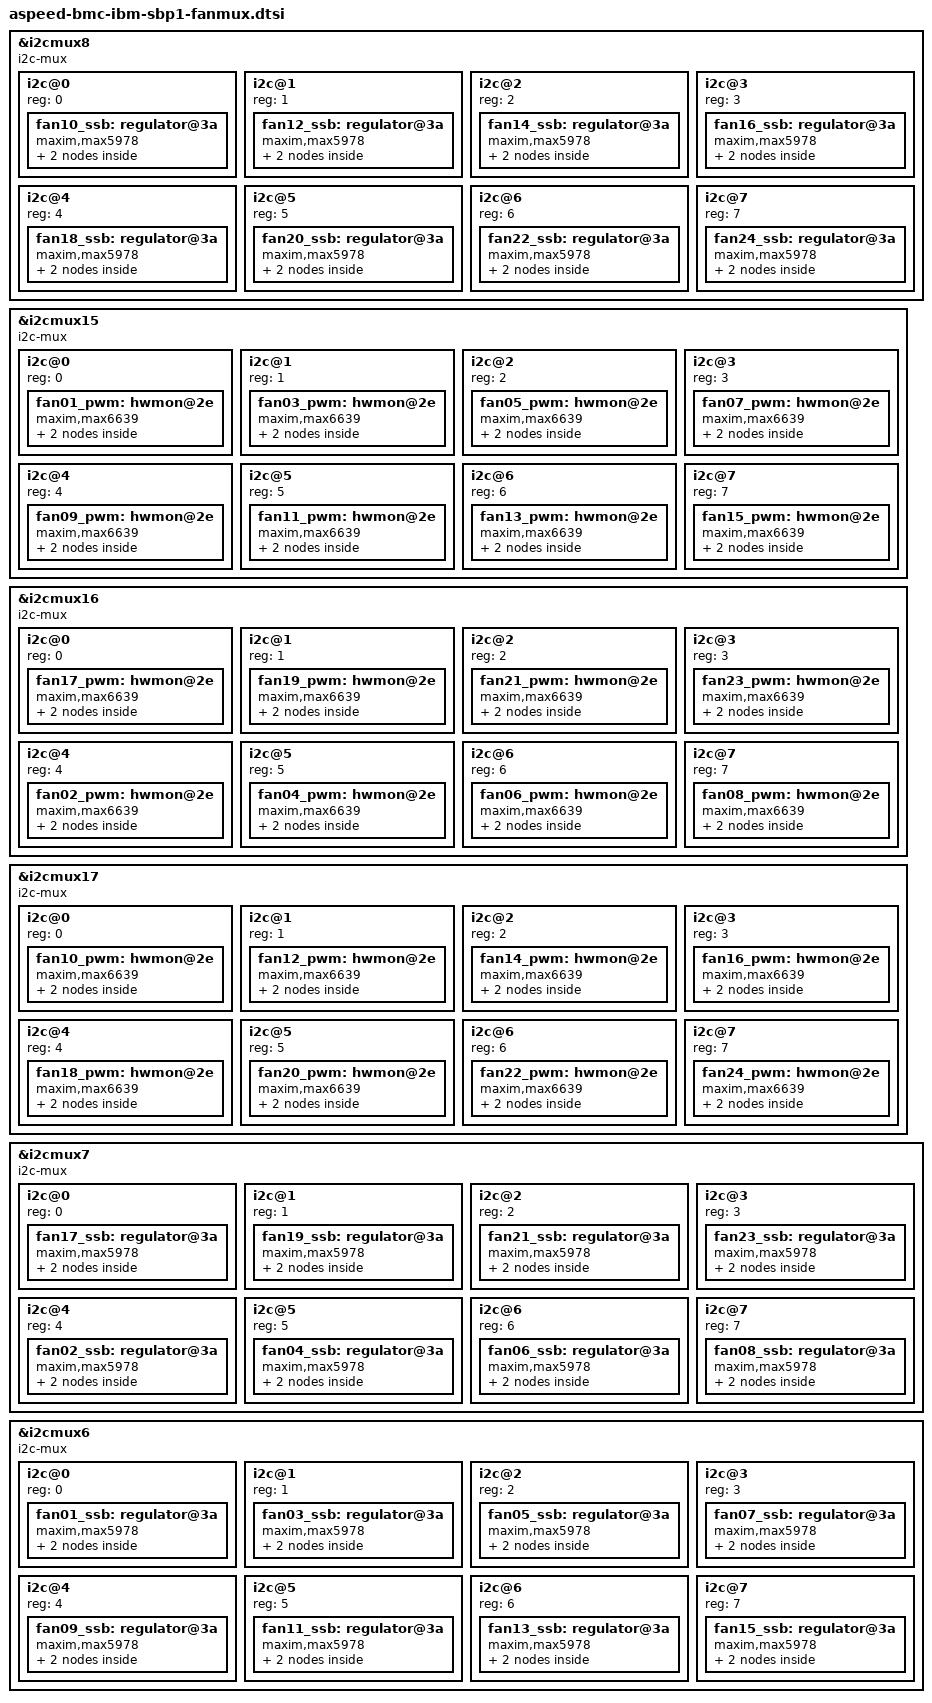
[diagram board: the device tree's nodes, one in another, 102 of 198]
&i2cmux8 {
	i2c@0 { // MUX_FAN10_SSB
		#address-cells = <1>;
		#size-cells = <0>;
		reg = <0>;
		fan10_ssb: regulator@3a {
			reg = <0x3a>;
			compatible = "maxim,max5978";
			#io-channel-cells = <1>;
			vin-supply = <&p3v3_aux>;
			vbus-supply = <&p3v3_aux>;
			vss1-supply = <&p12v_a>;
			interrupt-parent = <&smb_svc_pex_fan_alert>;
			interrupts = <9 IRQ_TYPE_LEVEL_LOW>; // FAN10_SSB_ALERT_N

			regulators {
				sw0_fan10_ssb: SW0 {
					vss1-supply = <&p12v_a>;
					regulator-compatible = "SW0";
					regulator-name = "fan10_supply";
					shunt-resistor-micro-ohms = <10000>;
					regulator-over-current-protection;
					regulator-oc-protection-microamp = <3400000>;
					regulator-enable-ramp-delay = <1000>;
				};
			};
		};

	};
	i2c@1 { // MUX_FAN12_SSB
		#address-cells = <1>;
		#size-cells = <0>;
		reg = <1>;
		fan12_ssb: regulator@3a {
			reg = <0x3a>;
			compatible = "maxim,max5978";
			#io-channel-cells = <1>;
			vin-supply = <&p3v3_aux>;
			vbus-supply = <&p3v3_aux>;
			vss1-supply = <&p12v_a>;
			interrupt-parent = <&smb_svc_pex_fan_alert>;
			interrupts = <11 IRQ_TYPE_LEVEL_LOW>; // FAN12_SSB_ALERT_N

			regulators {
				sw0_fan12_ssb: SW0 {
					vss1-supply = <&p12v_a>;
					regulator-compatible = "SW0";
					regulator-name = "fan12_supply";
					shunt-resistor-micro-ohms = <10000>;
					regulator-over-current-protection;
					regulator-oc-protection-microamp = <3400000>;
					regulator-enable-ramp-delay = <1000>;
				};
			};
		};

	};
	i2c@2 { // MUX_FAN14_SSB
		#address-cells = <1>;
		#size-cells = <0>;
		reg = <2>;
		fan14_ssb: regulator@3a {
			reg = <0x3a>;
			compatible = "maxim,max5978";
			#io-channel-cells = <1>;
			vin-supply = <&p3v3_aux>;
			vbus-supply = <&p3v3_aux>;
			vss1-supply = <&p12v_a>;
			interrupt-parent = <&smb_svc_pex_fan_alert>;
			interrupts = <13 IRQ_TYPE_LEVEL_LOW>; // FAN14_SSB_ALERT_N

			regulators {
				sw0_fan14_ssb: SW0 {
					vss1-supply = <&p12v_a>;
					regulator-compatible = "SW0";
					regulator-name = "fan14_supply";
					shunt-resistor-micro-ohms = <10000>;
					regulator-over-current-protection;
					regulator-oc-protection-microamp = <3400000>;
					regulator-enable-ramp-delay = <1000>;
				};
			};
		};
	};
	i2c@3 { // MUX_FAN16_SSB
		#address-cells = <1>;
		#size-cells = <0>;
		reg = <3>;
		fan16_ssb: regulator@3a {
			reg = <0x3a>;
			compatible = "maxim,max5978";
			#io-channel-cells = <1>;
			vin-supply = <&p3v3_aux>;
			vbus-supply = <&p3v3_aux>;
			vss1-supply = <&p12v_a>;
			interrupt-parent = <&smb_svc_pex_fan_alert>;
			interrupts = <15 IRQ_TYPE_LEVEL_LOW>; // FAN16_SSB_ALERT_N

			regulators {
				sw0_fan16_ssb: SW0 {
					vss1-supply = <&p12v_a>;
					regulator-compatible = "SW0";
					regulator-name = "fan16_supply";
					shunt-resistor-micro-ohms = <10000>;
					regulator-over-current-protection;
					regulator-oc-protection-microamp = <3400000>;
					regulator-enable-ramp-delay = <1000>;
				};
			};
		};
	};
	i2c@4 { // MUX_FAN18_SSB
		#address-cells = <1>;
		#size-cells = <0>;
		reg = <4>;
		fan18_ssb: regulator@3a {
			reg = <0x3a>;
			compatible = "maxim,max5978";
			#io-channel-cells = <1>;
			vin-supply = <&p3v3_aux>;
			vbus-supply = <&p3v3_aux>;
			vss1-supply = <&p12v_a>;
			interrupt-parent = <&smb_svc_pex_fan_alert>;
			interrupts = <17 IRQ_TYPE_LEVEL_LOW>; // FAN18_SSB_ALERT_N

			regulators {
				sw0_fan18_ssb: SW0 {
					vss1-supply = <&p12v_a>;
					regulator-compatible = "SW0";
					regulator-name = "fan18_supply";
					shunt-resistor-micro-ohms = <10000>;
					regulator-over-current-protection;
					regulator-oc-protection-microamp = <3400000>;
					regulator-enable-ramp-delay = <1000>;
				};
			};
		};
	};
	i2c@5 { // MUX_FAN20_SSB
		#address-cells = <1>;
		#size-cells = <0>;
		reg = <5>;
		fan20_ssb: regulator@3a {
			reg = <0x3a>;
			compatible = "maxim,max5978";
			#io-channel-cells = <1>;
			vin-supply = <&p3v3_aux>;
			vbus-supply = <&p3v3_aux>;
			vss1-supply = <&p12v_a>;
			interrupt-parent = <&smb_svc_pex_fan_alert>;
			interrupts = <19 IRQ_TYPE_LEVEL_LOW>; // FAN20_SSB_ALERT_N

			regulators {
				sw0_fan20_ssb: SW0 {
					vss1-supply = <&p12v_a>;
					regulator-compatible = "SW0";
					regulator-name = "fan20_supply";
					shunt-resistor-micro-ohms = <10000>;
					regulator-over-current-protection;
					regulator-oc-protection-microamp = <3400000>;
					regulator-enable-ramp-delay = <1000>;
				};
			};
		};
	};
	i2c@6 { // MUX_FAN22_SSB
		#address-cells = <1>;
		#size-cells = <0>;
		reg = <6>;
		fan22_ssb: regulator@3a {
			reg = <0x3a>;
			compatible = "maxim,max5978";
			#io-channel-cells = <1>;
			vin-supply = <&p3v3_aux>;
			vbus-supply = <&p3v3_aux>;
			vss1-supply = <&p12v_a>;
			interrupt-parent = <&smb_svc_pex_fan_alert>;
			interrupts = <21 IRQ_TYPE_LEVEL_LOW>; // FAN22_SSB_ALERT_N

			regulators {
				sw0_fan22_ssb: SW0 {
					vss1-supply = <&p12v_a>;
					regulator-compatible = "SW0";
					regulator-name = "fan22_supply";
					shunt-resistor-micro-ohms = <10000>;
					regulator-over-current-protection;
					regulator-oc-protection-microamp = <3400000>;
					regulator-enable-ramp-delay = <1000>;
				};
			};
		};
	};
	i2c@7 { // MUX_FAN24_SSB
		#address-cells = <1>;
		#size-cells = <0>;
		reg = <7>;
		fan24_ssb: regulator@3a {
			reg = <0x3a>;
			compatible = "maxim,max5978";
			#io-channel-cells = <1>;
			vin-supply = <&p3v3_aux>;
			vbus-supply = <&p3v3_aux>;
			vss1-supply = <&p12v_a>;
			interrupt-parent = <&smb_svc_pex_fan_alert>;
			interrupts = <23 IRQ_TYPE_LEVEL_LOW>; // FAN24_SSB_ALERT_N

			regulators {
				sw0_fan24_ssb: SW0 {
					vss1-supply = <&p12v_a>;
					regulator-compatible = "SW0";
					regulator-name = "fan24_supply";
					shunt-resistor-micro-ohms = <10000>;
					regulator-over-current-protection;
					regulator-oc-protection-microamp = <3400000>;
					regulator-enable-ramp-delay = <1000>;
				};
			};
		};
	};
};

&i2cmux15 {
	i2c@0 { // MUX_FAN01_PWM
		#address-cells = <1>;
		#size-cells = <0>;
		reg = <0>;
		fan01_pwm: hwmon@2e {
			compatible = "maxim,max6639";
			#address-cells = <1>;
			#size-cells = <0>;
			reg = <0x2e>;
			interrupt-parent = <&smb_svc_pex_fan_alert>;
			interrupts = <27 IRQ_TYPE_LEVEL_LOW>; // FAN01_PWM_ALERT_N
			fan-supply = <&sw0_fan01_ssb>;
			channel@0 {
				reg = <0>;
				pwm-polarity = <1>;
				pulses-per-revolution = <1>;
				rpm-range = <16000>;
				pwm-init = <90>;
				maxim,disable-therm-full-speed;
			};
			channel@1 {
				reg = <1>;
				pwm-polarity = <1>;
				pulses-per-revolution = <1>;
				rpm-range = <16000>;
				pwm-init = <90>;
				maxim,disable-therm-full-speed;
			};
		};
	};
	i2c@1 { // MUX_FAN03_PWM
		#address-cells = <1>;
		#size-cells = <0>;
		reg = <1>;
		fan03_pwm: hwmon@2e {
			compatible = "maxim,max6639";
			#address-cells = <1>;
			#size-cells = <0>;
			reg = <0x2e>;
			interrupt-parent = <&smb_svc_pex_fan_alert>;
			interrupts = <29 IRQ_TYPE_LEVEL_LOW>; // FAN03_PWM_ALERT_N
			fan-supply = <&sw0_fan03_ssb>;
			channel@0 {
				reg = <0>;
				pwm-polarity = <1>;
				pulses-per-revolution = <1>;
				rpm-range = <16000>;
				pwm-init = <90>;
				maxim,disable-therm-full-speed;
			};
			channel@1 {
				reg = <1>;
				pwm-polarity = <1>;
				pulses-per-revolution = <1>;
				rpm-range = <16000>;
				pwm-init = <90>;
				maxim,disable-therm-full-speed;
			};
		};
	};
	i2c@2 { // MUX_FAN05_PWM
		#address-cells = <1>;
		#size-cells = <0>;
		reg = <2>;
		fan05_pwm: hwmon@2e {
			compatible = "maxim,max6639";
			#address-cells = <1>;
			#size-cells = <0>;
			reg = <0x2e>;
			interrupt-parent = <&smb_svc_pex_fan_alert>;
			interrupts = <31 IRQ_TYPE_LEVEL_LOW>; // FAN05_PWM_ALERT_N
			fan-supply = <&sw0_fan05_ssb>;
			channel@0 {
				reg = <0>;
				pwm-polarity = <1>;
				pulses-per-revolution = <1>;
				rpm-range = <16000>;
				pwm-init = <90>;
				maxim,disable-therm-full-speed;
			};
			channel@1 {
				reg = <1>;
				pwm-polarity = <1>;
				pulses-per-revolution = <1>;
				rpm-range = <16000>;
				pwm-init = <90>;
				maxim,disable-therm-full-speed;
			};
		};
	};
	i2c@3 { // MUX_FAN07_PWM
		#address-cells = <1>;
		#size-cells = <0>;
		reg = <3>;
		fan07_pwm: hwmon@2e {
			compatible = "maxim,max6639";
			#address-cells = <1>;
			#size-cells = <0>;
			reg = <0x2e>;
			interrupt-parent = <&smb_svc_pex_fan_alert>;
			interrupts = <33 IRQ_TYPE_LEVEL_LOW>; // FAN07_PWM_ALERT_N
			fan-supply = <&sw0_fan07_ssb>;
			channel@0 {
				reg = <0>;
				pwm-polarity = <1>;
				pulses-per-revolution = <1>;
				rpm-range = <16000>;
				pwm-init = <90>;
				maxim,disable-therm-full-speed;
			};
			channel@1 {
				reg = <1>;
				pwm-polarity = <1>;
				pulses-per-revolution = <1>;
				rpm-range = <16000>;
				pwm-init = <90>;
				maxim,disable-therm-full-speed;
			};
		};
	};
	i2c@4 { // MUX_FAN09_PWM
		#address-cells = <1>;
		#size-cells = <0>;
		reg = <4>;
		fan09_pwm: hwmon@2e {
			compatible = "maxim,max6639";
			#address-cells = <1>;
			#size-cells = <0>;
			reg = <0x2e>;
			interrupt-parent = <&smb_svc_pex_fan_alert>;
			interrupts = <35 IRQ_TYPE_LEVEL_LOW>; // FAN09_PWM_ALERT_N
			fan-supply = <&sw0_fan09_ssb>;
			channel@0 {
				reg = <0>;
				pwm-polarity = <1>;
				pulses-per-revolution = <1>;
				rpm-range = <16000>;
				pwm-init = <90>;
				maxim,disable-therm-full-speed;
			};
			channel@1 {
				reg = <1>;
				pwm-polarity = <1>;
				pulses-per-revolution = <1>;
				rpm-range = <16000>;
				pwm-init = <90>;
				maxim,disable-therm-full-speed;
			};
		};
	};
	i2c@5 { // MUX_FAN11_PWM
		#address-cells = <1>;
		#size-cells = <0>;
		reg = <5>;
		fan11_pwm: hwmon@2e {
			compatible = "maxim,max6639";
			#address-cells = <1>;
			#size-cells = <0>;
			reg = <0x2e>;
			interrupt-parent = <&smb_svc_pex_fan_alert>;
			interrupts = <37 IRQ_TYPE_LEVEL_LOW>; // FAN11_PWM_ALERT_N
			fan-supply = <&sw0_fan11_ssb>;
			channel@0 {
				reg = <0>;
				pwm-polarity = <1>;
				pulses-per-revolution = <1>;
				rpm-range = <16000>;
				pwm-init = <90>;
				maxim,disable-therm-full-speed;
			};
			channel@1 {
				reg = <1>;
				pwm-polarity = <1>;
				pulses-per-revolution = <1>;
				rpm-range = <16000>;
				pwm-init = <90>;
				maxim,disable-therm-full-speed;
			};
		};
	};
	i2c@6 { // MUX_FAN13_PWM
		#address-cells = <1>;
		#size-cells = <0>;
		reg = <6>;
		fan13_pwm: hwmon@2e {
			compatible = "maxim,max6639";
			#address-cells = <1>;
			#size-cells = <0>;
			reg = <0x2e>;
			interrupt-parent = <&smb_svc_pex_fan_alert>;
			interrupts = <39 IRQ_TYPE_LEVEL_LOW>; // FAN13_PWM_ALERT_N
			fan-supply = <&sw0_fan13_ssb>;
			channel@0 {
				reg = <0>;
				pwm-polarity = <1>;
				pulses-per-revolution = <1>;
				rpm-range = <16000>;
				pwm-init = <90>;
				maxim,disable-therm-full-speed;
			};
			channel@1 {
				reg = <1>;
				pwm-polarity = <1>;
				pulses-per-revolution = <1>;
				rpm-range = <16000>;
				pwm-init = <90>;
				maxim,disable-therm-full-speed;
			};
		};
	};
	i2c@7 { // MUX_FAN15_PWM
		#address-cells = <1>;
		#size-cells = <0>;
		reg = <7>;
		fan15_pwm: hwmon@2e {
			compatible = "maxim,max6639";
			#address-cells = <1>;
			#size-cells = <0>;
			reg = <0x2e>;
			interrupt-parent = <&smb_svc_pex_fan_alert>;
			interrupts = <41 IRQ_TYPE_LEVEL_LOW>; // FAN15_PWM_ALERT_N
			fan-supply = <&sw0_fan15_ssb>;
			channel@0 {
				reg = <0>;
				pwm-polarity = <1>;
				pulses-per-revolution = <1>;
				rpm-range = <16000>;
				pwm-init = <90>;
				maxim,disable-therm-full-speed;
			};
			channel@1 {
				reg = <1>;
				pwm-polarity = <1>;
				pulses-per-revolution = <1>;
				rpm-range = <16000>;
				pwm-init = <90>;
				maxim,disable-therm-full-speed;
			};
		};
	};
};

&i2cmux16 {
	i2c@0 { // MUX_FAN17_PWM
		#address-cells = <1>;
		#size-cells = <0>;
		reg = <0>;
		fan17_pwm: hwmon@2e {
			compatible = "maxim,max6639";
			#address-cells = <1>;
			#size-cells = <0>;
			reg = <0x2e>;
			interrupt-parent = <&smb_svc_pex_fan_alert>;
			interrupts = <43 IRQ_TYPE_LEVEL_LOW>; // FAN17_PWM_ALERT_N
			fan-supply = <&sw0_fan17_ssb>;
			channel@0 {
				reg = <0>;
				pwm-polarity = <1>;
				pulses-per-revolution = <1>;
				rpm-range = <16000>;
				pwm-init = <90>;
				maxim,disable-therm-full-speed;
			};
			channel@1 {
				reg = <1>;
				pwm-polarity = <1>;
				pulses-per-revolution = <1>;
				rpm-range = <16000>;
				pwm-init = <90>;
				maxim,disable-therm-full-speed;
			};
		};
	};
	i2c@1 { // MUX_FAN19_PWM
		#address-cells = <1>;
		#size-cells = <0>;
		reg = <1>;
		fan19_pwm: hwmon@2e {
			compatible = "maxim,max6639";
			#address-cells = <1>;
			#size-cells = <0>;
			reg = <0x2e>;
			interrupt-parent = <&smb_svc_pex_fan_alert>;
			interrupts = <45 IRQ_TYPE_LEVEL_LOW>; // FAN19_PWM_ALERT_N
			fan-supply = <&sw0_fan19_ssb>;
			channel@0 {
				reg = <0>;
				pwm-polarity = <1>;
				pulses-per-revolution = <1>;
				rpm-range = <16000>;
				pwm-init = <90>;
				maxim,disable-therm-full-speed;
			};
			channel@1 {
				reg = <1>;
				pwm-polarity = <1>;
				pulses-per-revolution = <1>;
				rpm-range = <16000>;
				pwm-init = <90>;
				maxim,disable-therm-full-speed;
			};
		};
	};
	i2c@2 { // MUX_FAN21_PWM
		#address-cells = <1>;
		#size-cells = <0>;
		reg = <2>;
		fan21_pwm: hwmon@2e {
			compatible = "maxim,max6639";
			#address-cells = <1>;
			#size-cells = <0>;
			reg = <0x2e>;
			interrupt-parent = <&smb_svc_pex_fan_alert>;
			interrupts = <47 IRQ_TYPE_LEVEL_LOW>; // FAN21_PWM_ALERT_N
			fan-supply = <&sw0_fan21_ssb>;
			channel@0 {
				reg = <0>;
				pwm-polarity = <1>;
				pulses-per-revolution = <1>;
				rpm-range = <16000>;
				pwm-init = <90>;
				maxim,disable-therm-full-speed;
			};
			channel@1 {
				reg = <1>;
				pwm-polarity = <1>;
				pulses-per-revolution = <1>;
				rpm-range = <16000>;
				pwm-init = <90>;
				maxim,disable-therm-full-speed;
			};
		};
	};
	i2c@3 { // MUX_FAN23_PWM
		#address-cells = <1>;
		#size-cells = <0>;
		reg = <3>;
		fan23_pwm: hwmon@2e {
			compatible = "maxim,max6639";
			#address-cells = <1>;
			#size-cells = <0>;
			reg = <0x2e>;
			interrupt-parent = <&smb_svc_pex_fan_alert>;
			interrupts = <49 IRQ_TYPE_LEVEL_LOW>; // FAN23_PWM_ALERT_N
			fan-supply = <&sw0_fan23_ssb>;
			channel@0 {
				reg = <0>;
				pwm-polarity = <1>;
				pulses-per-revolution = <1>;
				rpm-range = <16000>;
				pwm-init = <90>;
				maxim,disable-therm-full-speed;
			};
			channel@1 {
				reg = <1>;
				pwm-polarity = <1>;
				pulses-per-revolution = <1>;
				rpm-range = <16000>;
				pwm-init = <90>;
				maxim,disable-therm-full-speed;
			};
		};
	};
	i2c@4 { // MUX_FAN02_PWM
		#address-cells = <1>;
		#size-cells = <0>;
		reg = <4>;
		fan02_pwm: hwmon@2e {
			compatible = "maxim,max6639";
			#address-cells = <1>;
			#size-cells = <0>;
			reg = <0x2e>;
			interrupt-parent = <&smb_svc_pex_fan_alert>;
			interrupts = <28 IRQ_TYPE_LEVEL_LOW>; // FAN02_PWM_ALERT_N
			fan-supply = <&sw0_fan02_ssb>;
			channel@0 {
				reg = <0>;
				pwm-polarity = <1>;
				pulses-per-revolution = <1>;
				rpm-range = <16000>;
				pwm-init = <90>;
				maxim,disable-therm-full-speed;
			};
			channel@1 {
				reg = <1>;
				pwm-polarity = <1>;
				pulses-per-revolution = <1>;
				rpm-range = <16000>;
				pwm-init = <90>;
				maxim,disable-therm-full-speed;
			};
		};
	};
	i2c@5 { // MUX_FAN04_PWM
		#address-cells = <1>;
		#size-cells = <0>;
		reg = <5>;
		fan04_pwm: hwmon@2e {
			compatible = "maxim,max6639";
			#address-cells = <1>;
			#size-cells = <0>;
			reg = <0x2e>;
			interrupt-parent = <&smb_svc_pex_fan_alert>;
			interrupts = <30 IRQ_TYPE_LEVEL_LOW>; // FAN04_PWM_ALERT_N
			fan-supply = <&sw0_fan04_ssb>;
			channel@0 {
				reg = <0>;
				pwm-polarity = <1>;
				pulses-per-revolution = <1>;
				rpm-range = <16000>;
				pwm-init = <90>;
				maxim,disable-therm-full-speed;
			};
			channel@1 {
				reg = <1>;
				pwm-polarity = <1>;
				pulses-per-revolution = <1>;
				rpm-range = <16000>;
				pwm-init = <90>;
				maxim,disable-therm-full-speed;
			};
		};
	};
	i2c@6 { // MUX_FAN06_PWM
		#address-cells = <1>;
		#size-cells = <0>;
		reg = <6>;
		fan06_pwm: hwmon@2e {
			compatible = "maxim,max6639";
			#address-cells = <1>;
			#size-cells = <0>;
			reg = <0x2e>;
			interrupt-parent = <&smb_svc_pex_fan_alert>;
			interrupts = <32 IRQ_TYPE_LEVEL_LOW>; // FAN06_PWM_ALERT_N
			fan-supply = <&sw0_fan06_ssb>;
			channel@0 {
				reg = <0>;
				pwm-polarity = <1>;
				pulses-per-revolution = <1>;
				rpm-range = <16000>;
				pwm-init = <90>;
				maxim,disable-therm-full-speed;
			};
			channel@1 {
				reg = <1>;
				pwm-polarity = <1>;
				pulses-per-revolution = <1>;
				rpm-range = <16000>;
				pwm-init = <90>;
				maxim,disable-therm-full-speed;
			};
		};
	};
	i2c@7 { // MUX_FAN08_PWM
		#address-cells = <1>;
		#size-cells = <0>;
		reg = <7>;
		fan08_pwm: hwmon@2e {
			compatible = "maxim,max6639";
			#address-cells = <1>;
			#size-cells = <0>;
			reg = <0x2e>;
			interrupt-parent = <&smb_svc_pex_fan_alert>;
			interrupts = <34 IRQ_TYPE_LEVEL_LOW>; // FAN08_PWM_ALERT_N
			fan-supply = <&sw0_fan08_ssb>;
			channel@0 {
				reg = <0>;
				pwm-polarity = <1>;
				pulses-per-revolution = <1>;
				rpm-range = <16000>;
				pwm-init = <90>;
				maxim,disable-therm-full-speed;
			};
			channel@1 {
				reg = <1>;
				pwm-polarity = <1>;
				pulses-per-revolution = <1>;
				rpm-range = <16000>;
				pwm-init = <90>;
				maxim,disable-therm-full-speed;
			};
		};
	};
};

&i2cmux17 {
	i2c@0 { // MUX_FAN10_PWM
		#address-cells = <1>;
		#size-cells = <0>;
		reg = <0>;
		fan10_pwm: hwmon@2e {
			compatible = "maxim,max6639";
			#address-cells = <1>;
			#size-cells = <0>;
			reg = <0x2e>;
			interrupt-parent = <&smb_svc_pex_fan_alert>;
			interrupts = <36 IRQ_TYPE_LEVEL_LOW>; // FAN10_PWM_ALERT_N
			fan-supply = <&sw0_fan10_ssb>;
			channel@0 {
				reg = <0x00>;
				pwm-polarity = <1>;
				pulses-per-revolution = <1>;
				rpm-range = <16000>;
				pwm-init = <90>;
				maxim,disable-therm-full-speed;
			};
			channel@1 {
				reg = <1>;
				pwm-polarity = <1>;
				pulses-per-revolution = <1>;
				rpm-range = <16000>;
				pwm-init = <90>;
				maxim,disable-therm-full-speed;
			};
		};
	};
	i2c@1 { // MUX_FAN12_PWM
		#address-cells = <1>;
		#size-cells = <0>;
		reg = <1>;
		fan12_pwm: hwmon@2e {
			compatible = "maxim,max6639";
			#address-cells = <1>;
			#size-cells = <0>;
			reg = <0x2e>;
			interrupt-parent = <&smb_svc_pex_fan_alert>;
			interrupts = <38 IRQ_TYPE_LEVEL_LOW>; // FAN12_PWM_ALERT_N
			fan-supply = <&sw0_fan12_ssb>;
			channel@0 {
				reg = <0>;
				pwm-polarity = <1>;
				pulses-per-revolution = <1>;
				rpm-range = <16000>;
				pwm-init = <90>;
				maxim,disable-therm-full-speed;
			};
			channel@1 {
				reg = <1>;
				pwm-polarity = <1>;
				pulses-per-revolution = <1>;
				rpm-range = <16000>;
				pwm-init = <90>;
				maxim,disable-therm-full-speed;
			};
		};
	};
	i2c@2 { // MUX_FAN14_PWM
		#address-cells = <1>;
		#size-cells = <0>;
		reg = <2>;
		fan14_pwm: hwmon@2e {
			compatible = "maxim,max6639";
			#address-cells = <1>;
			#size-cells = <0>;
			reg = <0x2e>;
			interrupt-parent = <&smb_svc_pex_fan_alert>;
			interrupts = <40 IRQ_TYPE_LEVEL_LOW>; // FAN14_PWM_ALERT_N
			fan-supply = <&sw0_fan14_ssb>;
			channel@0 {
				reg = <0>;
				pwm-polarity = <1>;
				pulses-per-revolution = <1>;
				rpm-range = <16000>;
				pwm-init = <90>;
				maxim,disable-therm-full-speed;
			};
			channel@1 {
				reg = <1>;
				pwm-polarity = <1>;
				pulses-per-revolution = <1>;
				rpm-range = <16000>;
				pwm-init = <90>;
				maxim,disable-therm-full-speed;
			};
		};
	};
	i2c@3 { // MUX_FAN16_PWM
		#address-cells = <1>;
		#size-cells = <0>;
		reg = <3>;
		fan16_pwm: hwmon@2e {
			compatible = "maxim,max6639";
			#address-cells = <1>;
			#size-cells = <0>;
			reg = <0x2e>;
			interrupt-parent = <&smb_svc_pex_fan_alert>;
			interrupts = <42 IRQ_TYPE_LEVEL_LOW>; // FAN16_PWM_ALERT_N
			fan-supply = <&sw0_fan16_ssb>;
			channel@0 {
				reg = <0>;
				pwm-polarity = <1>;
				pulses-per-revolution = <1>;
				rpm-range = <16000>;
				pwm-init = <90>;
				maxim,disable-therm-full-speed;
			};
			channel@1 {
				reg = <1>;
				pwm-polarity = <1>;
				pulses-per-revolution = <1>;
				rpm-range = <16000>;
				pwm-init = <90>;
				maxim,disable-therm-full-speed;
			};
		};
	};
	i2c@4 { // MUX_FAN18_PWM
		#address-cells = <1>;
		#size-cells = <0>;
		reg = <4>;
		fan18_pwm: hwmon@2e {
			compatible = "maxim,max6639";
			#address-cells = <1>;
			#size-cells = <0>;
			reg = <0x2e>;
			interrupt-parent = <&smb_svc_pex_fan_alert>;
			interrupts = <44 IRQ_TYPE_LEVEL_LOW>; // FAN18_PWM_ALERT_N
			fan-supply = <&sw0_fan18_ssb>;
			channel@0 {
				reg = <0>;
				pwm-polarity = <1>;
				pulses-per-revolution = <1>;
				rpm-range = <16000>;
				pwm-init = <90>;
				maxim,disable-therm-full-speed;
			};
			channel@1 {
				reg = <1>;
				pwm-polarity = <1>;
				pulses-per-revolution = <1>;
				rpm-range = <16000>;
				pwm-init = <90>;
				maxim,disable-therm-full-speed;
			};
		};
	};
	i2c@5 { // MUX_FAN20_PWM
		#address-cells = <1>;
		#size-cells = <0>;
		reg = <5>;
		fan20_pwm: hwmon@2e {
			compatible = "maxim,max6639";
			#address-cells = <1>;
			#size-cells = <0>;
			reg = <0x2e>;
			interrupt-parent = <&smb_svc_pex_fan_alert>;
			interrupts = <46 IRQ_TYPE_LEVEL_LOW>; // FAN20_PWM_ALERT_N
			fan-supply = <&sw0_fan20_ssb>;
			channel@0 {
				reg = <0>;
				pwm-polarity = <1>;
				pulses-per-revolution = <1>;
				rpm-range = <16000>;
				pwm-init = <90>;
				maxim,disable-therm-full-speed;
			};
			channel@1 {
				reg = <1>;
				pwm-polarity = <1>;
				pulses-per-revolution = <1>;
				rpm-range = <16000>;
				pwm-init = <90>;
				maxim,disable-therm-full-speed;
			};
		};
	};
	i2c@6 { // MUX_FAN22_PWM
		#address-cells = <1>;
		#size-cells = <0>;
		reg = <6>;
		fan22_pwm: hwmon@2e {
			compatible = "maxim,max6639";
			#address-cells = <1>;
			#size-cells = <0>;
			reg = <0x2e>;
			interrupt-parent = <&smb_svc_pex_fan_alert>;
			interrupts = <48 IRQ_TYPE_LEVEL_LOW>; // FAN22_PWM_ALERT_N
			fan-supply = <&sw0_fan22_ssb>;
			channel@0 {
				reg = <0>;
				pwm-polarity = <1>;
				pulses-per-revolution = <1>;
				rpm-range = <16000>;
				pwm-init = <90>;
				maxim,disable-therm-full-speed;
			};
			channel@1 {
				reg = <1>;
				pwm-polarity = <1>;
				pulses-per-revolution = <1>;
				rpm-range = <16000>;
				pwm-init = <90>;
				maxim,disable-therm-full-speed;
			};
		};
	};
	i2c@7 { // MUX_FAN24_PWM
		#address-cells = <1>;
		#size-cells = <0>;
		reg = <7>;
		fan24_pwm: hwmon@2e {
			compatible = "maxim,max6639";
			#address-cells = <1>;
			#size-cells = <0>;
			reg = <0x2e>;
			interrupt-parent = <&smb_svc_pex_fan_alert>;
			interrupts = <50 IRQ_TYPE_LEVEL_LOW>; // FAN24_PWM_ALERT_N
			fan-supply = <&sw0_fan24_ssb>;
			channel@0 {
				reg = <0>;
				pwm-polarity = <1>;
				pulses-per-revolution = <1>;
				rpm-range = <16000>;
				pwm-init = <90>;
				maxim,disable-therm-full-speed;
			};
			channel@1 {
				reg = <1>;
				pwm-polarity = <1>;
				pulses-per-revolution = <1>;
				rpm-range = <16000>;
				pwm-init = <90>;
				maxim,disable-therm-full-speed;
			};
		};
	};
};

&i2cmux7 {
	i2c@0 { // MUX_FAN17_SSB
		#address-cells = <1>;
		#size-cells = <0>;
		reg = <0>;
		fan17_ssb: regulator@3a {
			reg = <0x3a>;
			compatible = "maxim,max5978";
			#io-channel-cells = <1>;
			vin-supply = <&p3v3_aux>;
			vbus-supply = <&p3v3_aux>;
			vss1-supply = <&p12v_a>;
			interrupt-parent = <&smb_svc_pex_fan_alert>;
			interrupts = <16 IRQ_TYPE_LEVEL_LOW>; // FAN17_SSB_ALERT_N

			regulators {
				sw0_fan17_ssb: SW0 {
					vss1-supply = <&p12v_a>;
					regulator-compatible = "SW0";
					regulator-name = "fan17_supply";
					shunt-resistor-micro-ohms = <10000>;
					regulator-over-current-protection;
					regulator-oc-protection-microamp = <3400000>;
					regulator-enable-ramp-delay = <1000>;
				};
			};
		};
	};
	i2c@1 { // MUX_FAN19_SSB
		#address-cells = <1>;
		#size-cells = <0>;
		reg = <1>;
		fan19_ssb: regulator@3a {
			reg = <0x3a>;
			compatible = "maxim,max5978";
			#io-channel-cells = <1>;
			vin-supply = <&p3v3_aux>;
			vbus-supply = <&p3v3_aux>;
			vss1-supply = <&p12v_a>;
			interrupt-parent = <&smb_svc_pex_fan_alert>;
			interrupts = <18 IRQ_TYPE_LEVEL_LOW>; // FAN19_SSB_ALERT_N

			regulators {
				sw0_fan19_ssb: SW0 {
					vss1-supply = <&p12v_a>;
					regulator-compatible = "SW0";
					regulator-name = "fan19_supply";
					shunt-resistor-micro-ohms = <10000>;
					regulator-over-current-protection;
					regulator-oc-protection-microamp = <3400000>;
					regulator-enable-ramp-delay = <1000>;
				};
			};
		};
	};
	i2c@2 { // MUX_FAN21_SSB
		#address-cells = <1>;
		#size-cells = <0>;
		reg = <2>;
		fan21_ssb: regulator@3a {
			reg = <0x3a>;
			compatible = "maxim,max5978";
			#io-channel-cells = <1>;
			vin-supply = <&p3v3_aux>;
			vbus-supply = <&p3v3_aux>;
			vss1-supply = <&p12v_a>;
			interrupt-parent = <&smb_svc_pex_fan_alert>;
			interrupts = <20 IRQ_TYPE_LEVEL_LOW>; // FAN21_SSB_ALERT_N

			regulators {
				sw0_fan21_ssb: SW0 {
					vss1-supply = <&p12v_a>;
					regulator-compatible = "SW0";
					regulator-name = "fan21_supply";
					shunt-resistor-micro-ohms = <10000>;
					regulator-over-current-protection;
					regulator-oc-protection-microamp = <3400000>;
					regulator-enable-ramp-delay = <1000>;
				};
			};
		};
	};
	i2c@3 { // MUX_FAN23_SSB
		#address-cells = <1>;
		#size-cells = <0>;
		reg = <3>;
		fan23_ssb: regulator@3a {
			reg = <0x3a>;
			compatible = "maxim,max5978";
			#io-channel-cells = <1>;
			vin-supply = <&p3v3_aux>;
			vbus-supply = <&p3v3_aux>;
			vss1-supply = <&p12v_a>;
			interrupt-parent = <&smb_svc_pex_fan_alert>;
			interrupts = <22 IRQ_TYPE_LEVEL_LOW>; // FAN23_SSB_ALERT_N

			regulators {
				sw0_fan23_ssb: SW0 {
					vss1-supply = <&p12v_a>;
					regulator-compatible = "SW0";
					regulator-name = "fan23_supply";
					shunt-resistor-micro-ohms = <10000>;
					regulator-over-current-protection;
					regulator-oc-protection-microamp = <3400000>;
					regulator-enable-ramp-delay = <1000>;
				};
			};
		};
	};
	i2c@4 { // MUX_FAN02_SSB
		#address-cells = <1>;
		#size-cells = <0>;
		reg = <4>;
		fan02_ssb: regulator@3a {
			reg = <0x3a>;
			compatible = "maxim,max5978";
			#io-channel-cells = <1>;
			vin-supply = <&p3v3_aux>;
			vbus-supply = <&p3v3_aux>;
			vss1-supply = <&p12v_a>;
			interrupt-parent = <&smb_svc_pex_fan_alert>;
			interrupts = <1 IRQ_TYPE_LEVEL_LOW>; // FAN02_SSB_ALERT_N

			regulators {
				sw0_fan02_ssb: SW0 {
					vss1-supply = <&p12v_a>;
					regulator-compatible = "SW0";
					regulator-name = "fan02_supply";
					shunt-resistor-micro-ohms = <10000>;
					regulator-over-current-protection;
					regulator-oc-protection-microamp = <3400000>;
					regulator-enable-ramp-delay = <1000>;
				};
			};
		};
	};
	i2c@5 { // MUX_FAN04_SSB
		#address-cells = <1>;
		#size-cells = <0>;
		reg = <5>;
		fan04_ssb: regulator@3a {
			reg = <0x3a>;
			compatible = "maxim,max5978";
			#io-channel-cells = <1>;
			vin-supply = <&p3v3_aux>;
			vbus-supply = <&p3v3_aux>;
			vss1-supply = <&p12v_a>;
			interrupt-parent = <&smb_svc_pex_fan_alert>;
			interrupts = <3 IRQ_TYPE_LEVEL_LOW>; // FAN04_SSB_ALERT_N

			regulators {
				sw0_fan04_ssb: SW0 {
					vss1-supply = <&p12v_a>;
					regulator-compatible = "SW0";
					regulator-name = "fan04_supply";
					shunt-resistor-micro-ohms = <10000>;
					regulator-over-current-protection;
					regulator-oc-protection-microamp = <3400000>;
					regulator-enable-ramp-delay = <1000>;
				};
			};
		};
	};
	i2c@6 { // MUX_FAN06_SSB
		#address-cells = <1>;
		#size-cells = <0>;
		reg = <6>;
		fan06_ssb: regulator@3a {
			reg = <0x3a>;
			compatible = "maxim,max5978";
			#io-channel-cells = <1>;
			vin-supply = <&p3v3_aux>;
			vbus-supply = <&p3v3_aux>;
			vss1-supply = <&p12v_a>;
			interrupt-parent = <&smb_svc_pex_fan_alert>;
			interrupts = <5 IRQ_TYPE_LEVEL_LOW>; // FAN06_SSB_ALERT_N

			regulators {
				sw0_fan06_ssb: SW0 {
					vss1-supply = <&p12v_a>;
					regulator-compatible = "SW0";
					regulator-name = "fan06_supply";
					shunt-resistor-micro-ohms = <10000>;
					regulator-over-current-protection;
					regulator-oc-protection-microamp = <3400000>;
					regulator-enable-ramp-delay = <1000>;
				};
			};
		};
	};
	i2c@7 { // MUX_FAN08_SSB
		#address-cells = <1>;
		#size-cells = <0>;
		reg = <7>;
		fan08_ssb: regulator@3a {
			reg = <0x3a>;
			compatible = "maxim,max5978";
			#io-channel-cells = <1>;
			vin-supply = <&p3v3_aux>;
			vbus-supply = <&p3v3_aux>;
			vss1-supply = <&p12v_a>;
			interrupt-parent = <&smb_svc_pex_fan_alert>;
			interrupts = <7 IRQ_TYPE_LEVEL_LOW>; // FAN08_SSB_ALERT_N

			regulators {
				sw0_fan08_ssb: SW0 {
					vss1-supply = <&p12v_a>;
					regulator-compatible = "SW0";
					regulator-name = "fan08_supply";
					shunt-resistor-micro-ohms = <10000>;
					regulator-over-current-protection;
					regulator-oc-protection-microamp = <3400000>;
					regulator-enable-ramp-delay = <1000>;
				};
			};
		};
	};
};


&i2cmux6 {
	i2c@0 { // MUX_FAN01_SSB
		#address-cells = <1>;
		#size-cells = <0>;
		reg = <0>;
		fan01_ssb: regulator@3a {
			reg = <0x3a>;
			compatible = "maxim,max5978";
			#io-channel-cells = <1>;
			vin-supply = <&p3v3_aux>;
			vbus-supply = <&p3v3_aux>;
			vss1-supply = <&p12v_a>;
			interrupt-parent = <&smb_svc_pex_fan_alert>;
			interrupts = <0 IRQ_TYPE_LEVEL_LOW>; // FAN01_SSB_ALERT_N

			regulators {
				sw0_fan01_ssb: SW0 {
					vss1-supply = <&p12v_a>;
					regulator-compatible = "SW0";
					regulator-name = "fan01_supply";
					shunt-resistor-micro-ohms = <10000>;
					regulator-over-current-protection;
					regulator-oc-protection-microamp = <3400000>;
					regulator-enable-ramp-delay = <1000>;
				};
			};
		};
	};
	i2c@1 { // MUX_FAN03_SSB
		#address-cells = <1>;
		#size-cells = <0>;
		reg = <1>;
		fan03_ssb: regulator@3a {
			reg = <0x3a>;
			compatible = "maxim,max5978";
			#io-channel-cells = <1>;
			vin-supply = <&p3v3_aux>;
			vbus-supply = <&p3v3_aux>;
			vss1-supply = <&p12v_a>;
			interrupt-parent = <&smb_svc_pex_fan_alert>;
			interrupts = <2 IRQ_TYPE_LEVEL_LOW>; // FAN03_SSB_ALERT_N

			regulators {
				sw0_fan03_ssb: SW0 {
					vss1-supply = <&p12v_a>;
					regulator-name = "fan03_supply";
					regulator-compatible = "SW0";
					shunt-resistor-micro-ohms = <10000>;
					regulator-over-current-protection;
					regulator-oc-protection-microamp = <3400000>;
					regulator-enable-ramp-delay = <1000>;
				};
			};
		};
	};
	i2c@2 { // MUX_FAN05_SSB
		#address-cells = <1>;
		#size-cells = <0>;
		reg = <2>;
		fan05_ssb: regulator@3a {
			reg = <0x3a>;
			compatible = "maxim,max5978";
			#io-channel-cells = <1>;
			vin-supply = <&p3v3_aux>;
			vbus-supply = <&p3v3_aux>;
			vss1-supply = <&p12v_a>;
			interrupt-parent = <&smb_svc_pex_fan_alert>;
			interrupts = <4 IRQ_TYPE_LEVEL_LOW>; // FAN05_SSB_ALERT_N

			regulators {
				sw0_fan05_ssb: SW0 {
					vss1-supply = <&p12v_a>;
					regulator-compatible = "SW0";
					regulator-name = "fan05_supply";
					shunt-resistor-micro-ohms = <10000>;
					regulator-over-current-protection;
					regulator-oc-protection-microamp = <3400000>;
					regulator-enable-ramp-delay = <1000>;
				};
			};
		};
	};
	i2c@3 { // MUX_FAN07_SSB
		#address-cells = <1>;
		#size-cells = <0>;
		reg = <3>;
		fan07_ssb: regulator@3a {
			reg = <0x3a>;
			compatible = "maxim,max5978";
			#io-channel-cells = <1>;
			vin-supply = <&p3v3_aux>;
			vbus-supply = <&p3v3_aux>;
			vss1-supply = <&p12v_a>;
			interrupt-parent = <&smb_svc_pex_fan_alert>;
			interrupts = <6 IRQ_TYPE_LEVEL_LOW>; // FAN07_SSB_ALERT_N

			regulators {
				sw0_fan07_ssb: SW0 {
					vss1-supply = <&p12v_a>;
					regulator-compatible = "SW0";
					regulator-name = "fan07_supply";
					shunt-resistor-micro-ohms = <10000>;
					regulator-over-current-protection;
					regulator-oc-protection-microamp = <3400000>;
					regulator-enable-ramp-delay = <1000>;
				};
			};
		};
	};
	i2c@4 { // MUX_FAN09_SSB
		#address-cells = <1>;
		#size-cells = <0>;
		reg = <4>;
		fan09_ssb: regulator@3a {
			reg = <0x3a>;
			compatible = "maxim,max5978";
			#io-channel-cells = <1>;
			vin-supply = <&p3v3_aux>;
			vbus-supply = <&p3v3_aux>;
			vss1-supply = <&p12v_a>;
			interrupt-parent = <&smb_svc_pex_fan_alert>;
			interrupts = <8 IRQ_TYPE_LEVEL_LOW>; // FAN09_SSB_ALERT_N

			regulators {
				sw0_fan09_ssb: SW0 {
					vss1-supply = <&p12v_a>;
					regulator-compatible = "SW0";
					regulator-name = "fan09_supply";
					shunt-resistor-micro-ohms = <10000>;
					regulator-over-current-protection;
					regulator-oc-protection-microamp = <3400000>;
					regulator-enable-ramp-delay = <1000>;
				};
			};
		};
	};
	i2c@5 { // MUX_FAN11_SSB
		#address-cells = <1>;
		#size-cells = <0>;
		reg = <5>;
		fan11_ssb: regulator@3a {
			reg = <0x3a>;
			compatible = "maxim,max5978";
			#io-channel-cells = <1>;
			vin-supply = <&p3v3_aux>;
			vbus-supply = <&p3v3_aux>;
			vss1-supply = <&p12v_a>;
			interrupt-parent = <&smb_svc_pex_fan_alert>;
			interrupts = <10 IRQ_TYPE_LEVEL_LOW>; // FAN11_SSB_ALERT_N

			regulators {
				sw0_fan11_ssb: SW0 {
					vss1-supply = <&p12v_a>;
					regulator-compatible = "SW0";
					regulator-name = "fan11_supply";
					shunt-resistor-micro-ohms = <10000>;
					regulator-over-current-protection;
					regulator-oc-protection-microamp = <3400000>;
					regulator-enable-ramp-delay = <1000>;
				};
			};
		};
	};
	i2c@6 { // MUX_FAN13_SSB
		#address-cells = <1>;
		#size-cells = <0>;
		reg = <6>;
		fan13_ssb: regulator@3a {
			reg = <0x3a>;
			compatible = "maxim,max5978";
			#io-channel-cells = <1>;
			vin-supply = <&p3v3_aux>;
			vbus-supply = <&p3v3_aux>;
			vss1-supply = <&p12v_a>;
			interrupt-parent = <&smb_svc_pex_fan_alert>;
			interrupts = <12 IRQ_TYPE_LEVEL_LOW>; // FAN13_SSB_ALERT_N

			regulators {
				sw0_fan13_ssb: SW0 {
					vss1-supply = <&p12v_a>;
					regulator-compatible = "SW0";
					regulator-name = "fan13_supply";
					shunt-resistor-micro-ohms = <10000>;
					regulator-over-current-protection;
					regulator-oc-protection-microamp = <3400000>;
					regulator-enable-ramp-delay = <1000>;
				};
			};
		};
	};
	i2c@7 { // MUX_FAN15_SSB
		#address-cells = <1>;
		#size-cells = <0>;
		reg = <7>;
		fan15_ssb: regulator@3a {
			reg = <0x3a>;
			compatible = "maxim,max5978";
			#io-channel-cells = <1>;
			vin-supply = <&p3v3_aux>;
			vbus-supply = <&p3v3_aux>;
			vss1-supply = <&p12v_a>;
			interrupt-parent = <&smb_svc_pex_fan_alert>;
			interrupts = <14 IRQ_TYPE_LEVEL_LOW>; // FAN15_SSB_ALERT_N

			regulators {
				sw0_fan15_ssb: SW0 {
					vss1-supply = <&p12v_a>;
					regulator-compatible = "SW0";
					regulator-name = "fan15_supply";
					shunt-resistor-micro-ohms = <10000>;
					regulator-over-current-protection;
					regulator-oc-protection-microamp = <3400000>;
					regulator-enable-ramp-delay = <1000>;
				};
			};
		};

	};
};
